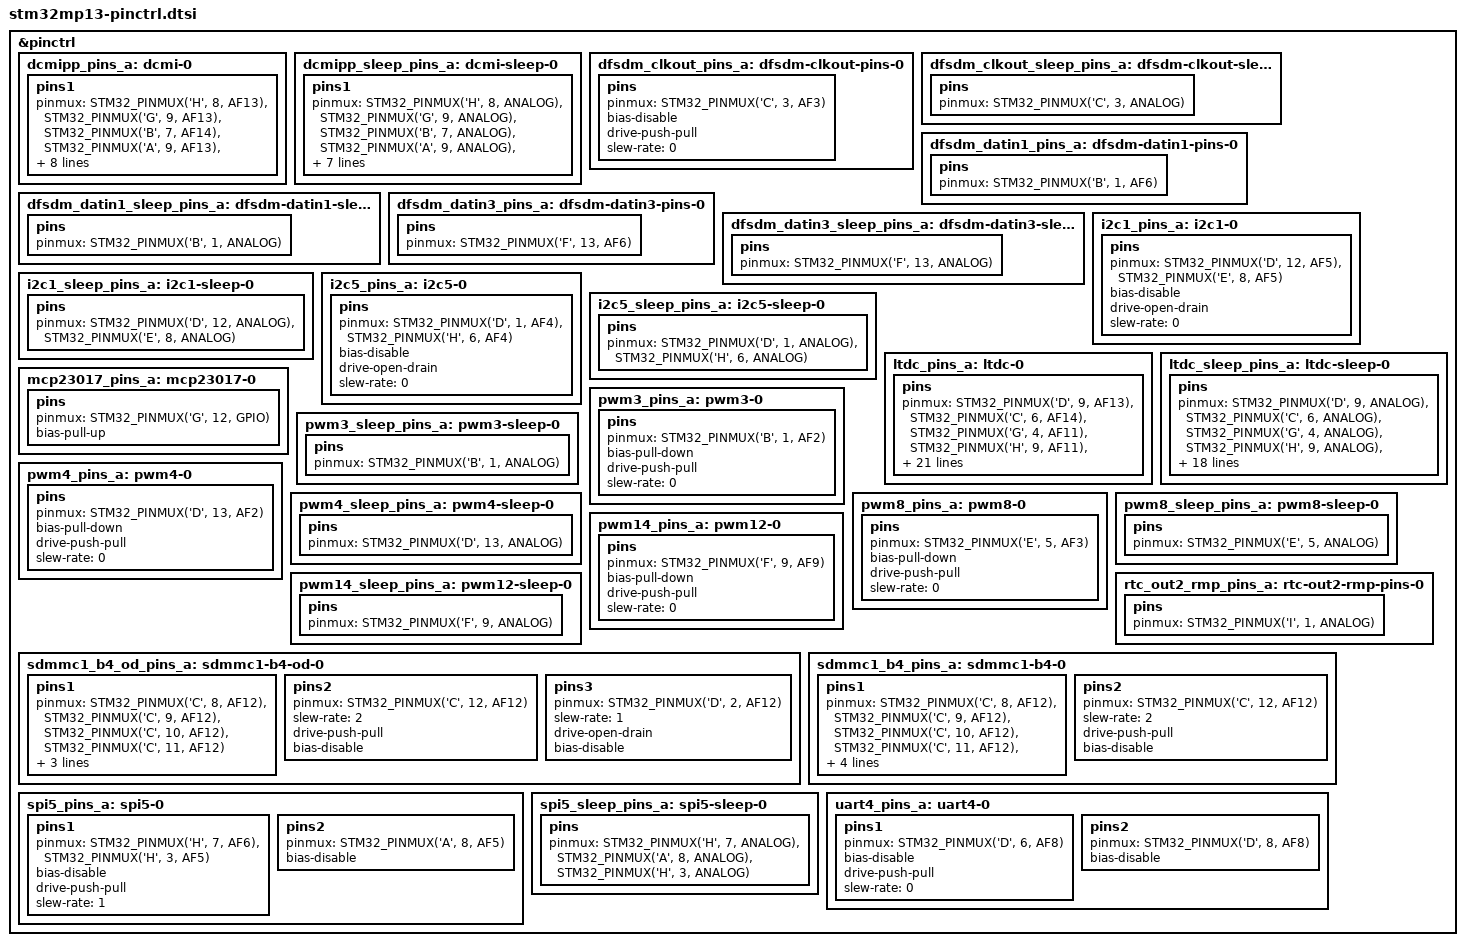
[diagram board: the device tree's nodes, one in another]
// SPDX-License-Identifier: (GPL-2.0+ OR BSD-3-Clause)
/*
 * Copyright (C) STMicroelectronics 2021 - All Rights Reserved
 * Author: Alexandre Torgue <alexandre.torgue@foss.st.com>
 */
#include <dt-bindings/pinctrl/stm32-pinfunc.h>

&pinctrl {
	dcmipp_pins_a: dcmi-0 {
		pins1 {
			pinmux = <STM32_PINMUX('H',  8,  AF13)>,/* DCMI_HSYNC */
				 <STM32_PINMUX('G',  9,  AF13)>,/* DCMI_VSYNC */
				 <STM32_PINMUX('B',  7,  AF14)>,/* DCMI_PIXCLK */
				 <STM32_PINMUX('A',  9,  AF13)>,/* DCMI_D0 */
				 <STM32_PINMUX('D',  0,  AF13)>,/* DCMI_D1 */
				 <STM32_PINMUX('G', 10,  AF13)>,/* DCMI_D2 */
				 <STM32_PINMUX('E',  4,  AF13)>,/* DCMI_D3 */
				 <STM32_PINMUX('D', 11,  AF14)>,/* DCMI_D4 */
				 <STM32_PINMUX('D',  3,  AF13)>,/* DCMI_D5 */
				 <STM32_PINMUX('B',  8,  AF13)>,/* DCMI_D6 */
				 <STM32_PINMUX('E', 14,  AF13)>;/* DCMI_D7 */
			bias-disable;
		};
	};

	dcmipp_sleep_pins_a: dcmi-sleep-0 {
		pins1 {
			pinmux = <STM32_PINMUX('H',  8,  ANALOG)>,/* DCMI_HSYNC */
				 <STM32_PINMUX('G',  9,  ANALOG)>,/* DCMI_VSYNC */
				 <STM32_PINMUX('B',  7,  ANALOG)>,/* DCMI_PIXCLK */
				 <STM32_PINMUX('A',  9,  ANALOG)>,/* DCMI_D0 */
				 <STM32_PINMUX('D',  0,  ANALOG)>,/* DCMI_D1 */
				 <STM32_PINMUX('G', 10,  ANALOG)>,/* DCMI_D2 */
				 <STM32_PINMUX('E',  4,  ANALOG)>,/* DCMI_D3 */
				 <STM32_PINMUX('D', 11,  ANALOG)>,/* DCMI_D4 */
				 <STM32_PINMUX('D',  3,  ANALOG)>,/* DCMI_D5 */
				 <STM32_PINMUX('B',  8,  ANALOG)>,/* DCMI_D6 */
				 <STM32_PINMUX('E', 14,  ANALOG)>;/* DCMI_D7 */
		};
	};

	dfsdm_clkout_pins_a: dfsdm-clkout-pins-0 {
		pins {
			pinmux = <STM32_PINMUX('C', 3, AF3)>; /* DFSDM_CKOUT */
			bias-disable;
			drive-push-pull;
			slew-rate = <0>;
		};
	};

	dfsdm_clkout_sleep_pins_a: dfsdm-clkout-sleep-pins-0 {
		pins {
			pinmux = <STM32_PINMUX('C', 3, ANALOG)>; /* DFSDM_CKOUT */
		};
	};

	dfsdm_datin1_pins_a: dfsdm-datin1-pins-0 {
		pins {
			pinmux = <STM32_PINMUX('B', 1, AF6)>; /* DFSDM_DATIN1 */
		};
	};

	dfsdm_datin1_sleep_pins_a: dfsdm-datin1-sleep-pins-0 {
		pins {
			pinmux = <STM32_PINMUX('B', 1, ANALOG)>; /* DFSDM_DATIN1 */
		};
	};

	dfsdm_datin3_pins_a: dfsdm-datin3-pins-0 {
		pins {
			pinmux = <STM32_PINMUX('F', 13, AF6)>; /* DFSDM_DATIN3 */
		};
	};

	dfsdm_datin3_sleep_pins_a: dfsdm-datin3-sleep-pins-0 {
		pins {
			pinmux = <STM32_PINMUX('F', 13, ANALOG)>; /* DFSDM_DATIN3 */
		};
	};

	i2c1_pins_a: i2c1-0 {
		pins {
			pinmux = <STM32_PINMUX('D', 12, AF5)>, /* I2C1_SCL */
				 <STM32_PINMUX('E', 8, AF5)>; /* I2C1_SDA */
			bias-disable;
			drive-open-drain;
			slew-rate = <0>;
		};
	};

	i2c1_sleep_pins_a: i2c1-sleep-0 {
		pins {
			pinmux = <STM32_PINMUX('D', 12, ANALOG)>, /* I2C1_SCL */
				 <STM32_PINMUX('E', 8, ANALOG)>; /* I2C1_SDA */
		};
	};

	i2c5_pins_a: i2c5-0 {
		pins {
			pinmux = <STM32_PINMUX('D', 1, AF4)>, /* I2C5_SCL */
				 <STM32_PINMUX('H', 6, AF4)>; /* I2C5_SDA */
			bias-disable;
			drive-open-drain;
			slew-rate = <0>;
		};
	};

	i2c5_sleep_pins_a: i2c5-sleep-0 {
		pins {
			pinmux = <STM32_PINMUX('D', 1, ANALOG)>, /* I2C5_SCL */
				 <STM32_PINMUX('H', 6, ANALOG)>; /* I2C5_SDA */
		};
	};

	ltdc_pins_a: ltdc-0 {
		pins {
			pinmux = <STM32_PINMUX('D',  9, AF13)>, /* LCD_CLK */
				 <STM32_PINMUX('C',  6, AF14)>, /* LCD_HSYNC */
				 <STM32_PINMUX('G',  4, AF11)>, /* LCD_VSYNC */
				 <STM32_PINMUX('H',  9, AF11)>, /* LCD_DE */
				 <STM32_PINMUX('G',  7, AF14)>, /* LCD_R2 */
				 <STM32_PINMUX('B', 12, AF13)>, /* LCD_R3 */
				 <STM32_PINMUX('D', 14, AF14)>, /* LCD_R4 */
				 <STM32_PINMUX('E',  7, AF14)>, /* LCD_R5 */
				 <STM32_PINMUX('E', 13, AF14)>, /* LCD_R6 */
				 <STM32_PINMUX('E',  9, AF14)>, /* LCD_R7 */
				 <STM32_PINMUX('H', 13, AF14)>, /* LCD_G2 */
				 <STM32_PINMUX('F',  3, AF14)>, /* LCD_G3 */
				 <STM32_PINMUX('D',  5, AF14)>, /* LCD_G4 */
				 <STM32_PINMUX('G',  0, AF14)>, /* LCD_G5 */
				 <STM32_PINMUX('C',  7, AF14)>, /* LCD_G6 */
				 <STM32_PINMUX('A', 15, AF11)>, /* LCD_G7 */
				 <STM32_PINMUX('D', 10, AF14)>, /* LCD_B2 */
				 <STM32_PINMUX('F',  2, AF14)>, /* LCD_B3 */
				 <STM32_PINMUX('H', 14, AF11)>, /* LCD_B4 */
				 <STM32_PINMUX('E',  0, AF14)>, /* LCD_B5 */
				 <STM32_PINMUX('B',  6, AF7)>,  /* LCD_B6 */
				 <STM32_PINMUX('F',  1, AF13)>; /* LCD_B7 */
			bias-disable;
			drive-push-pull;
			slew-rate = <0>;
		};
	};

	ltdc_sleep_pins_a: ltdc-sleep-0 {
		pins {
			pinmux = <STM32_PINMUX('D',  9, ANALOG)>, /* LCD_CLK */
				 <STM32_PINMUX('C',  6, ANALOG)>, /* LCD_HSYNC */
				 <STM32_PINMUX('G',  4, ANALOG)>, /* LCD_VSYNC */
				 <STM32_PINMUX('H',  9, ANALOG)>, /* LCD_DE */
				 <STM32_PINMUX('G',  7, ANALOG)>, /* LCD_R2 */
				 <STM32_PINMUX('B', 12, ANALOG)>, /* LCD_R3 */
				 <STM32_PINMUX('D', 14, ANALOG)>, /* LCD_R4 */
				 <STM32_PINMUX('E',  7, ANALOG)>, /* LCD_R5 */
				 <STM32_PINMUX('E', 13, ANALOG)>, /* LCD_R6 */
				 <STM32_PINMUX('E',  9, ANALOG)>, /* LCD_R7 */
				 <STM32_PINMUX('H', 13, ANALOG)>, /* LCD_G2 */
				 <STM32_PINMUX('F',  3, ANALOG)>, /* LCD_G3 */
				 <STM32_PINMUX('D',  5, ANALOG)>, /* LCD_G4 */
				 <STM32_PINMUX('G',  0, ANALOG)>, /* LCD_G5 */
				 <STM32_PINMUX('C',  7, ANALOG)>, /* LCD_G6 */
				 <STM32_PINMUX('A', 15, ANALOG)>, /* LCD_G7 */
				 <STM32_PINMUX('D', 10, ANALOG)>, /* LCD_B2 */
				 <STM32_PINMUX('F',  2, ANALOG)>, /* LCD_B3 */
				 <STM32_PINMUX('H', 14, ANALOG)>, /* LCD_B4 */
				 <STM32_PINMUX('E',  0, ANALOG)>, /* LCD_B5 */
				 <STM32_PINMUX('B',  6, ANALOG)>, /* LCD_B6 */
				 <STM32_PINMUX('F',  1, ANALOG)>; /* LCD_B7 */
		};
	};

	mcp23017_pins_a: mcp23017-0 {
		pins {
			pinmux = <STM32_PINMUX('G', 12, GPIO)>;
			bias-pull-up;
		};
	};

	pwm3_pins_a: pwm3-0 {
		pins {
			pinmux = <STM32_PINMUX('B', 1, AF2)>; /* TIM3_CH4 */
			bias-pull-down;
			drive-push-pull;
			slew-rate = <0>;
		};
	};

	pwm3_sleep_pins_a: pwm3-sleep-0 {
		pins {
			pinmux = <STM32_PINMUX('B', 1, ANALOG)>; /* TIM3_CH4 */
		};
	};

	pwm4_pins_a: pwm4-0 {
		pins {
			pinmux = <STM32_PINMUX('D', 13, AF2)>; /* TIM4_CH2 */
			bias-pull-down;
			drive-push-pull;
			slew-rate = <0>;
		};
	};

	pwm4_sleep_pins_a: pwm4-sleep-0 {
		pins {
			pinmux = <STM32_PINMUX('D', 13, ANALOG)>; /* TIM4_CH2 */
		};
	};

	pwm8_pins_a: pwm8-0 {
		pins {
			pinmux = <STM32_PINMUX('E', 5, AF3)>; /* TIM8_CH3 */
			bias-pull-down;
			drive-push-pull;
			slew-rate = <0>;
		};
	};

	pwm8_sleep_pins_a: pwm8-sleep-0 {
		pins {
			pinmux = <STM32_PINMUX('E', 5, ANALOG)>; /* TIM8_CH3 */
		};
	};

	pwm14_pins_a: pwm12-0 {
		pins {
			pinmux = <STM32_PINMUX('F', 9, AF9)>; /* TIM14_CH1 */
			bias-pull-down;
			drive-push-pull;
			slew-rate = <0>;
		};
	};

	pwm14_sleep_pins_a: pwm12-sleep-0 {
		pins {
			pinmux = <STM32_PINMUX('F', 9, ANALOG)>; /* TIM14_CH1 */
		};
	};

	rtc_out2_rmp_pins_a: rtc-out2-rmp-pins-0 {
		pins {
			pinmux = <STM32_PINMUX('I', 1, ANALOG)>; /* RTC_OUT2_RMP */
		};
	};

	sdmmc1_b4_od_pins_a: sdmmc1-b4-od-0 {
		pins1 {
			pinmux = <STM32_PINMUX('C', 8, AF12)>, /* SDMMC1_D0 */
				 <STM32_PINMUX('C', 9, AF12)>, /* SDMMC1_D1 */
				 <STM32_PINMUX('C', 10, AF12)>, /* SDMMC1_D2 */
				 <STM32_PINMUX('C', 11, AF12)>; /* SDMMC1_D3 */
			slew-rate = <1>;
			drive-push-pull;
			bias-disable;
		};
		pins2 {
			pinmux = <STM32_PINMUX('C', 12, AF12)>; /* SDMMC1_CK */
			slew-rate = <2>;
			drive-push-pull;
			bias-disable;
		};
		pins3 {
			pinmux = <STM32_PINMUX('D', 2, AF12)>; /* SDMMC1_CMD */
			slew-rate = <1>;
			drive-open-drain;
			bias-disable;
		};
	};

	sdmmc1_b4_pins_a: sdmmc1-b4-0 {
		pins1 {
			pinmux = <STM32_PINMUX('C', 8, AF12)>, /* SDMMC1_D0 */
				 <STM32_PINMUX('C', 9, AF12)>, /* SDMMC1_D1 */
				 <STM32_PINMUX('C', 10, AF12)>, /* SDMMC1_D2 */
				 <STM32_PINMUX('C', 11, AF12)>, /* SDMMC1_D3 */
				 <STM32_PINMUX('D', 2, AF12)>; /* SDMMC1_CMD */
			slew-rate = <1>;
			drive-push-pull;
			bias-disable;
		};
		pins2 {
			pinmux = <STM32_PINMUX('C', 12, AF12)>; /* SDMMC1_CK */
			slew-rate = <2>;
			drive-push-pull;
			bias-disable;
		};
	};

	spi5_pins_a: spi5-0 {
		pins1 {
			pinmux = <STM32_PINMUX('H', 7, AF6)>, /* SPI5_SCK */
				 <STM32_PINMUX('H', 3, AF5)>; /* SPI5_MOSI */
			bias-disable;
			drive-push-pull;
			slew-rate = <1>;
		};

		pins2 {
			pinmux = <STM32_PINMUX('A', 8, AF5)>; /* SPI5_MISO */
			bias-disable;
		};
	};

	spi5_sleep_pins_a: spi5-sleep-0 {
		pins {
			pinmux = <STM32_PINMUX('H', 7, ANALOG)>, /* SPI5_SCK */
				 <STM32_PINMUX('A', 8, ANALOG)>, /* SPI5_MISO */
				 <STM32_PINMUX('H', 3, ANALOG)>; /* SPI5_MOSI */
		};
	};

	uart4_pins_a: uart4-0 {
		pins1 {
			pinmux = <STM32_PINMUX('D', 6, AF8)>; /* UART4_TX */
			bias-disable;
			drive-push-pull;
			slew-rate = <0>;
		};
		pins2 {
			pinmux = <STM32_PINMUX('D', 8, AF8)>; /* UART4_RX */
			bias-disable;
		};
	};
};
